VERSION ""

NS_ :

BS_:

BU_: Buf1 Buf2 Buf3

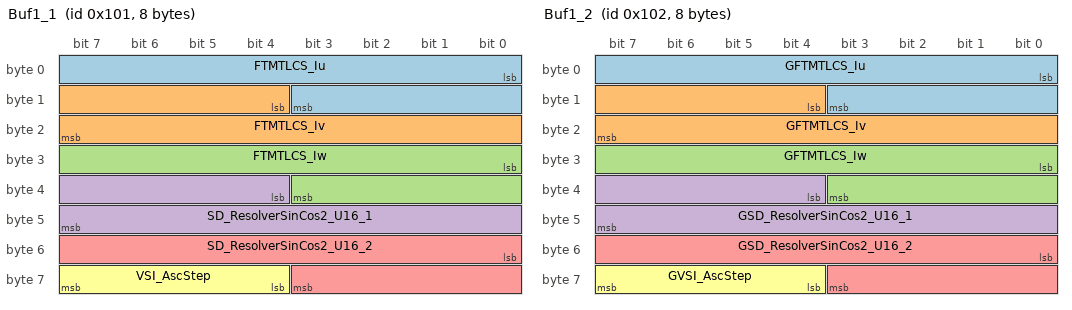
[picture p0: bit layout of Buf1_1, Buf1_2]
BO_ 257 Buf1_1: 8 Buf1
 SG_ FTMTLCS_Iu : 0|12@1+ (1,-2000) [-2000|2095] "" Vector__XXX
 SG_ FTMTLCS_Iv : 12|12@1+ (1,-2000) [-2000|2095] "" Vector__XXX
 SG_ FTMTLCS_Iw : 24|12@1+ (1,-2000) [-2000|2095] "" Vector__XXX
 SG_ SD_ResolverSinCos2_U16_1 : 36|12@1+ (1,0) [0|4095] "" Vector__XXX
 SG_ SD_ResolverSinCos2_U16_2 : 48|12@1+ (1,0) [0|4095] "" Vector__XXX
 SG_ VSI_AscStep : 60|4@1+ (1,0) [0|15] "" Vector__XXX

BO_ 258 Buf1_2: 8 Buf1
 SG_ GFTMTLCS_Iu : 0|12@1+ (1,-2000) [-2000|2095] "" Vector__XXX
 SG_ GFTMTLCS_Iv : 12|12@1+ (1,-2000) [-2000|2095] "" Vector__XXX
 SG_ GFTMTLCS_Iw : 24|12@1+ (1,-2000) [-2000|2095] "" Vector__XXX
 SG_ GSD_ResolverSinCos2_U16_1 : 36|12@1+ (1,0) [0|4095] "" Vector__XXX
 SG_ GSD_ResolverSinCos2_U16_2 : 48|12@1+ (1,0) [0|4095] "" Vector__XXX
 SG_ GVSI_AscStep : 60|4@1+ (1,0) [0|15] "" Vector__XXX

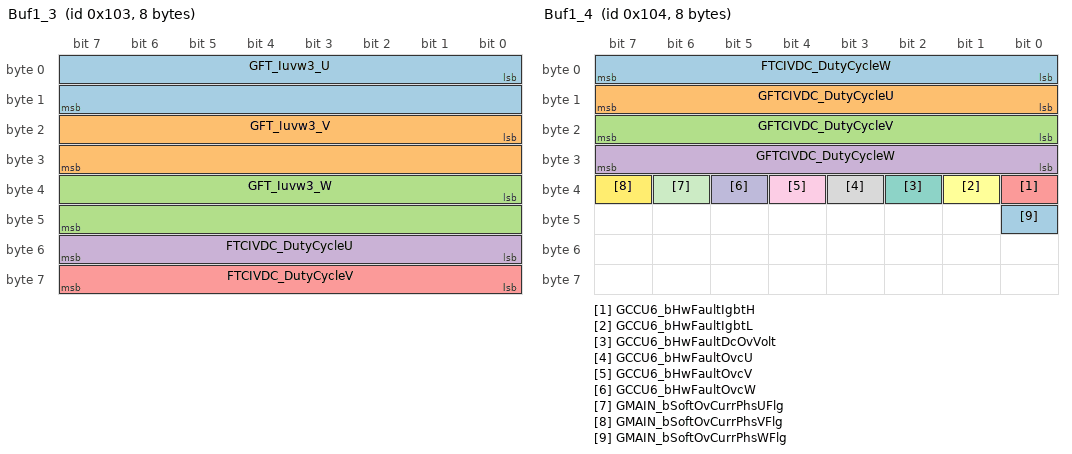
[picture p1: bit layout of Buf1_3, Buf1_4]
BO_ 259 Buf1_3: 8 Buf1
 SG_ GFT_Iuvw3_U : 0|16@1+ (1,0) [0|65535] "" Vector__XXX
 SG_ GFT_Iuvw3_V : 16|16@1+ (1,0) [0|65535] "" Vector__XXX
 SG_ GFT_Iuvw3_W : 32|16@1+ (1,0) [0|65535] "" Vector__XXX
 SG_ FTCIVDC_DutyCycleU : 48|8@1+ (0.01,-1) [-1|1.55] "" Vector__XXX
 SG_ FTCIVDC_DutyCycleV : 56|8@1+ (0.01,-1) [-1|1.55] "" Vector__XXX

BO_ 260 Buf1_4: 8 Buf1
 SG_ FTCIVDC_DutyCycleW : 0|8@1+ (0.01,-1) [-1|1.55] "" Vector__XXX
 SG_ GFTCIVDC_DutyCycleU : 8|8@1+ (0.01,-1) [-1|1.55] "" Vector__XXX
 SG_ GFTCIVDC_DutyCycleV : 16|8@1+ (0.01,-1) [-1|1.55] "" Vector__XXX
 SG_ GFTCIVDC_DutyCycleW : 24|8@1+ (0.01,-1) [-1|1.55] "" Vector__XXX
 SG_ GCCU6_bHwFaultIgbtH : 32|1@1+ (1,0) [0|1] "" Vector__XXX
 SG_ GCCU6_bHwFaultIgbtL : 33|1@1+ (1,0) [0|1] "" Vector__XXX
 SG_ GCCU6_bHwFaultDcOvVolt : 34|1@1+ (1,0) [0|1] "" Vector__XXX
 SG_ GCCU6_bHwFaultOvcU : 35|1@1+ (1,0) [0|1] "" Vector__XXX
 SG_ GCCU6_bHwFaultOvcV : 36|1@1+ (1,0) [0|1] "" Vector__XXX
 SG_ GCCU6_bHwFaultOvcW : 37|1@1+ (1,0) [0|1] "" Vector__XXX
 SG_ GMAIN_bSoftOvCurrPhsUFlg : 38|1@1+ (1,0) [0|1] "" Vector__XXX
 SG_ GMAIN_bSoftOvCurrPhsVFlg : 39|1@1+ (1,0) [0|1] "" Vector__XXX
 SG_ GMAIN_bSoftOvCurrPhsWFlg : 40|1@1+ (1,0) [0|1] "" Vector__XXX

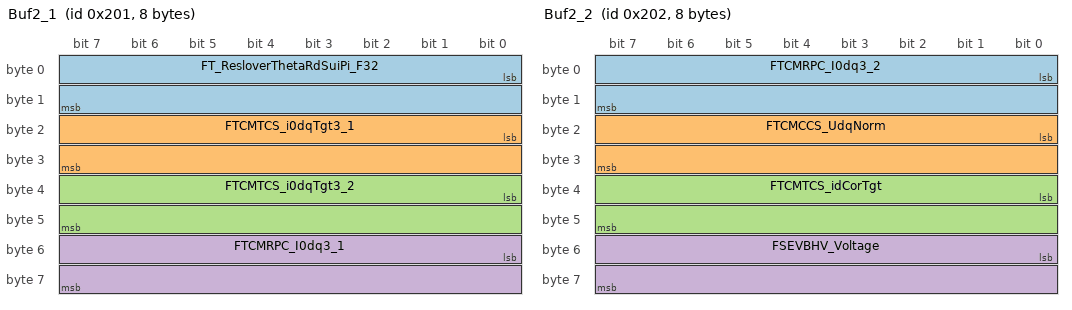
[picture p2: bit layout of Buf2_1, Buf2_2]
BO_ 513 Buf2_1: 8 Buf2
 SG_ FT_ResloverThetaRdSuiPi_F32 : 0|16@1+ (0.001,-4) [-4|61.535] "" Vector__XXX
 SG_ FTCMTCS_i0dqTgt3_1 : 16|16@1+ (1,-5000) [-5000|60535] "" Vector__XXX
 SG_ FTCMTCS_i0dqTgt3_2 : 32|16@1+ (1,-5000) [-5000|60535] "" Vector__XXX
 SG_ FTCMRPC_I0dq3_1 : 48|16@1+ (1,-5000) [-5000|60535] "" Vector__XXX

BO_ 514 Buf2_2: 8 Buf2
 SG_ FTCMRPC_I0dq3_2 : 0|16@1+ (1,-5000) [-5000|60535] "" Vector__XXX
 SG_ FTCMCCS_UdqNorm : 16|16@1+ (1,0) [0|65535] "" Vector__XXX
 SG_ FTCMTCS_idCorTgt : 32|16@1+ (1,-5000) [-5000|60535] "" Vector__XXX
 SG_ FSEVBHV_Voltage : 48|16@1+ (1,0) [0|65535] "" Vector__XXX

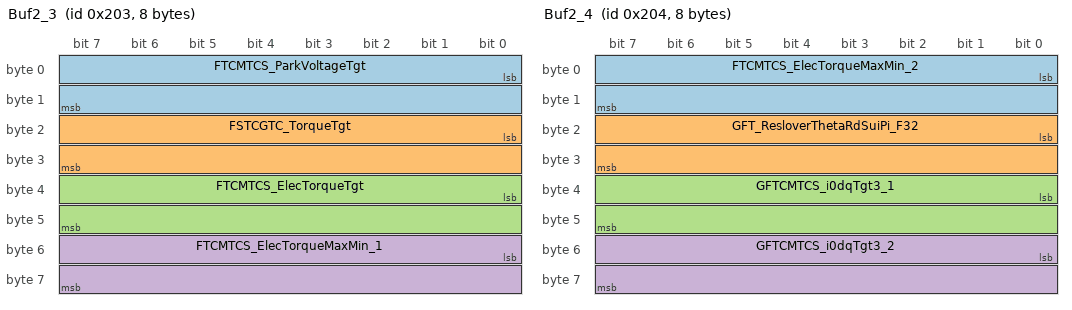
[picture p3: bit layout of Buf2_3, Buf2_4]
BO_ 515 Buf2_3: 8 Buf2
 SG_ FTCMTCS_ParkVoltageTgt : 0|16@1+ (0.1,0) [0|6553.5] "" Vector__XXX
 SG_ FSTCGTC_TorqueTgt : 16|16@1+ (0.1,-1500) [-1500|5053.5] "" Vector__XXX
 SG_ FTCMTCS_ElecTorqueTgt : 32|16@1+ (0.1,-1500) [-1500|5053.5] "" Vector__XXX
 SG_ FTCMTCS_ElecTorqueMaxMin_1 : 48|16@1+ (0.1,0) [0|65535] "" Vector__XXX

BO_ 516 Buf2_4: 8 Buf2
 SG_ FTCMTCS_ElecTorqueMaxMin_2 : 0|16@1+ (0.1,-1500) [-1500|5053.5] "" Vector__XXX
 SG_ GFT_ResloverThetaRdSuiPi_F32 : 16|16@1+ (0.001,-4) [-4|61.535] "" Vector__XXX
 SG_ GFTCMTCS_i0dqTgt3_1 : 32|16@1+ (1,-5000) [-5000|60535] "" Vector__XXX
 SG_ GFTCMTCS_i0dqTgt3_2 : 48|16@1+ (1,-5000) [-5000|60535] "" Vector__XXX

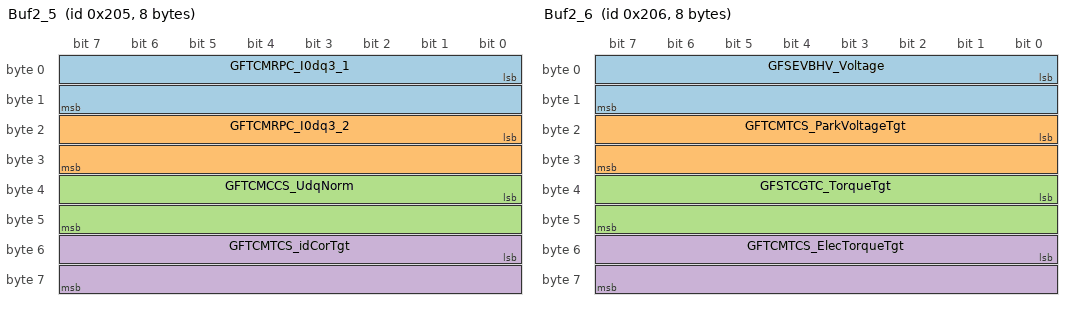
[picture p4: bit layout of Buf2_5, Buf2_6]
BO_ 517 Buf2_5: 8 Buf2
 SG_ GFTCMRPC_I0dq3_1 : 0|16@1+ (1,-5000) [-5000|60535] "" Vector__XXX
 SG_ GFTCMRPC_I0dq3_2 : 16|16@1+ (1,-5000) [-5000|60535] "" Vector__XXX
 SG_ GFTCMCCS_UdqNorm : 32|16@1+ (1,0) [0|65535] "" Vector__XXX
 SG_ GFTCMTCS_idCorTgt : 48|16@1+ (1,-5000) [-50000|60535] "" Vector__XXX

BO_ 518 Buf2_6: 8 Buf2
 SG_ GFSEVBHV_Voltage : 0|16@1+ (1,0) [0|65535] "" Vector__XXX
 SG_ GFTCMTCS_ParkVoltageTgt : 16|16@1+ (0.1,0) [0|6553.5] "" Vector__XXX
 SG_ GFSTCGTC_TorqueTgt : 32|16@1+ (0.1,-1500) [-1500|5053.5] "" Vector__XXX
 SG_ GFTCMTCS_ElecTorqueTgt : 48|16@1+ (0.1,-1500) [-1500|5053.5] "" Vector__XXX

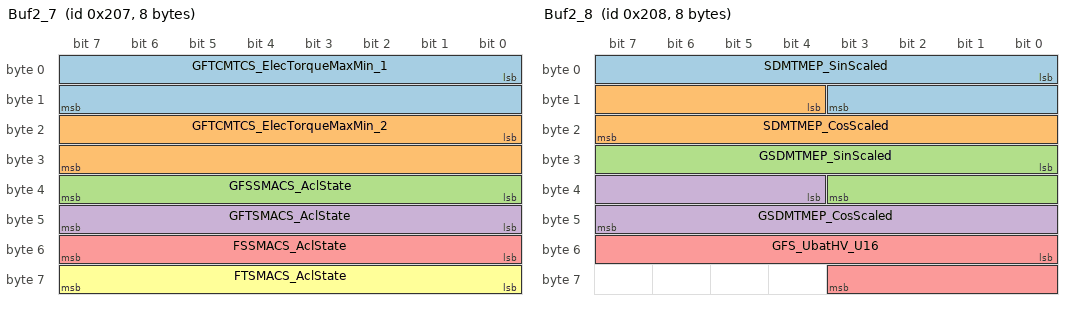
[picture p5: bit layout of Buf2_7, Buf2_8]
BO_ 519 Buf2_7: 8 Buf2
 SG_ GFTCMTCS_ElecTorqueMaxMin_1 : 0|16@1+ (0.1,0) [0|6553.5] "" Vector__XXX
 SG_ GFTCMTCS_ElecTorqueMaxMin_2 : 16|16@1+ (0.1,-1500) [-1500|5053.5] "" Vector__XXX
 SG_ GFSSMACS_AclState : 32|8@1+ (1,0) [0|255] "" Vector__XXX
 SG_ GFTSMACS_AclState : 40|8@1+ (1,0) [0|255] "" Vector__XXX
 SG_ FSSMACS_AclState : 48|8@1+ (1,0) [0|255] "" Vector__XXX
 SG_ FTSMACS_AclState : 56|8@1+ (1,0) [0|255] "" Vector__XXX

BO_ 520 Buf2_8: 8 Buf2
 SG_ SDMTMEP_SinScaled : 0|12@1+ (1,0) [0|4095] "" Vector__XXX
 SG_ SDMTMEP_CosScaled : 12|12@1+ (1,0) [0|4095] "" Vector__XXX
 SG_ GSDMTMEP_SinScaled : 24|12@1+ (1,0) [0|4095] "" Vector__XXX
 SG_ GSDMTMEP_CosScaled : 36|12@1+ (1,0) [0|4095] "" Vector__XXX
 SG_ GFS_UbatHV_U16 : 48|12@1+ (1,0) [0|4095] "" Vector__XXX

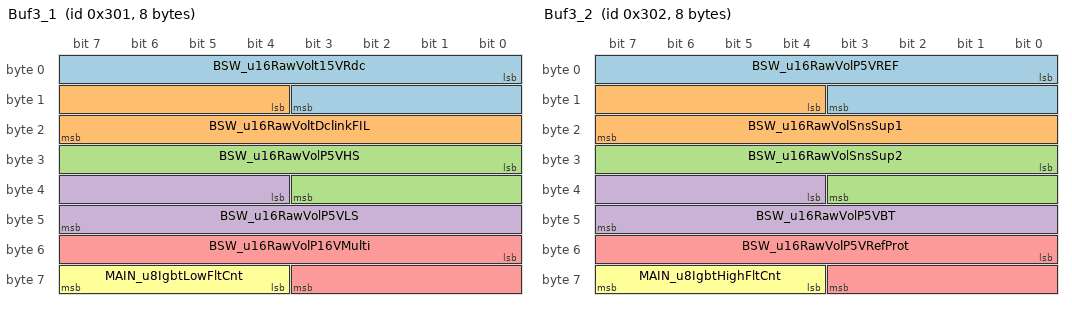
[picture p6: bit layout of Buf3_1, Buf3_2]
BO_ 769 Buf3_1: 8 Buf3
 SG_ BSW_u16RawVolt15VRdc : 0|12@1+ (1,0) [0|4095] "" Vector__XXX
 SG_ BSW_u16RawVoltDclinkFIL : 12|12@1+ (1,0) [0|4095] "" Vector__XXX
 SG_ BSW_u16RawVolP5VHS : 24|12@1+ (1,0) [0|4095] "" Vector__XXX
 SG_ BSW_u16RawVolP5VLS : 36|12@1+ (1,0) [0|4095] "" Vector__XXX
 SG_ BSW_u16RawVolP16VMulti : 48|12@1+ (1,0) [0|4095] "" Vector__XXX
 SG_ MAIN_u8IgbtLowFltCnt : 60|4@1+ (1,0) [0|15] "" Vector__XXX

BO_ 770 Buf3_2: 8 Buf3
 SG_ BSW_u16RawVolP5VREF : 0|12@1+ (1,0) [0|4095] "" Vector__XXX
 SG_ BSW_u16RawVolSnsSup1 : 12|12@1+ (1,0) [0|4095] "" Vector__XXX
 SG_ BSW_u16RawVolSnsSup2 : 24|12@1+ (1,0) [0|4095] "" Vector__XXX
 SG_ BSW_u16RawVolP5VBT : 36|12@1+ (1,0) [0|4095] "" Vector__XXX
 SG_ BSW_u16RawVolP5VRefProt : 48|12@1+ (1,0) [0|4095] "" Vector__XXX
 SG_ MAIN_u8IgbtHighFltCnt : 60|4@1+ (1,0) [0|15] "" Vector__XXX

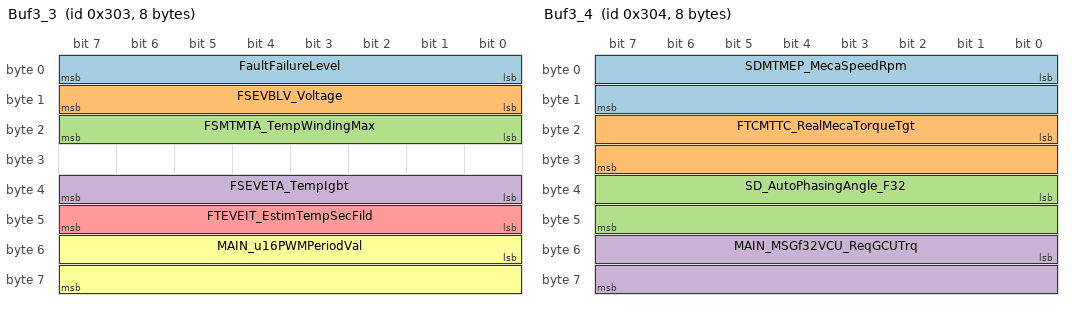
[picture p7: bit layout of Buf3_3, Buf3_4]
BO_ 771 Buf3_3: 8 Buf3
 SG_ FaultFailureLevel : 0|8@1+ (1,0) [0|255] "" Vector__XXX
 SG_ FSEVBLV_Voltage : 8|8@1+ (0.2,0) [0|51] "" Vector__XXX
 SG_ FSMTMTA_TempWindingMax : 16|8@1+ (1,-50) [-50|205] "" Vector__XXX
 SG_ FSEVETA_TempIgbt : 32|8@1+ (1,-50) [-50|205] "" Vector__XXX
 SG_ FTEVEIT_EstimTempSecFild : 40|8@1+ (1,-50) [-50|205] "" Vector__XXX
 SG_ MAIN_u16PWMPeriodVal : 48|16@1+ (1,0) [0|65535] "" Vector__XXX

BO_ 772 Buf3_4: 8 Buf3
 SG_ SDMTMEP_MecaSpeedRpm : 0|16@1+ (1,-20000) [-20000|45535] "" Vector__XXX
 SG_ FTCMTTC_RealMecaTorqueTgt : 16|16@1+ (0.1,-3000) [-3000|3553.5] "" Vector__XXX
 SG_ SD_AutoPhasingAngle_F32 : 32|16@1+ (0.0001,-3) [-3|3.5535] "" Vector__XXX
 SG_ MAIN_MSGf32VCU_ReqGCUTrq : 48|16@1+ (1,-1024) [-1024|64511] "" Vector__XXX

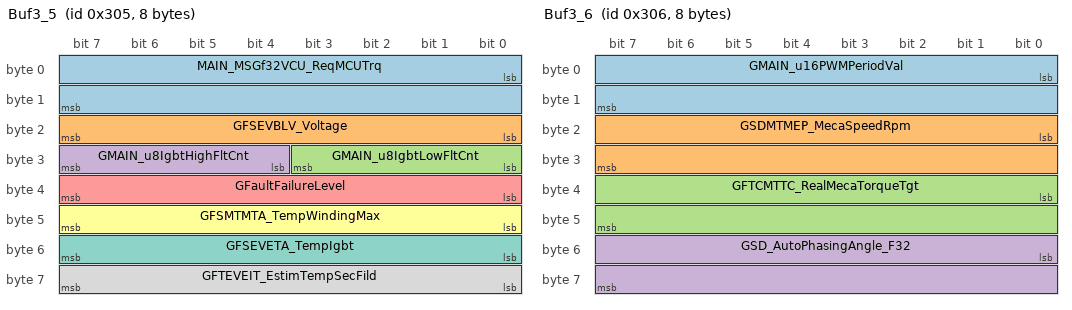
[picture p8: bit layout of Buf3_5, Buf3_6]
BO_ 773 Buf3_5: 8 Buf3
 SG_ MAIN_MSGf32VCU_ReqMCUTrq : 0|16@1+ (1,-1024) [-1024|64511] "" Vector__XXX
 SG_ GFSEVBLV_Voltage : 16|8@1+ (0.2,0) [0|51] "" Vector__XXX
 SG_ GMAIN_u8IgbtLowFltCnt : 24|4@1+ (1,0) [0|15] "" Vector__XXX
 SG_ GMAIN_u8IgbtHighFltCnt : 28|4@1+ (1,0) [0|15] "" Vector__XXX
 SG_ GFaultFailureLevel : 32|8@1+ (1,0) [0|255] "" Vector__XXX
 SG_ GFSMTMTA_TempWindingMax : 40|8@1+ (1,-50) [-50|205] "" Vector__XXX
 SG_ GFSEVETA_TempIgbt : 48|8@1+ (1,-50) [-50|205] "" Vector__XXX
 SG_ GFTEVEIT_EstimTempSecFild : 56|8@1+ (1,-50) [-50|205] "" Vector__XXX

BO_ 774 Buf3_6: 8 Buf3
 SG_ GMAIN_u16PWMPeriodVal : 0|16@1+ (1,0) [0|65535] "" Vector__XXX
 SG_ GSDMTMEP_MecaSpeedRpm : 16|16@1+ (1,-20000) [-20000|45535] "" Vector__XXX
 SG_ GFTCMTTC_RealMecaTorqueTgt : 32|16@1+ (0.1,-3000) [-3000|3553.5] "" Vector__XXX
 SG_ GSD_AutoPhasingAngle_F32 : 48|16@1+ (0.0001,-3) [-3|3.5535] "" Vector__XXX

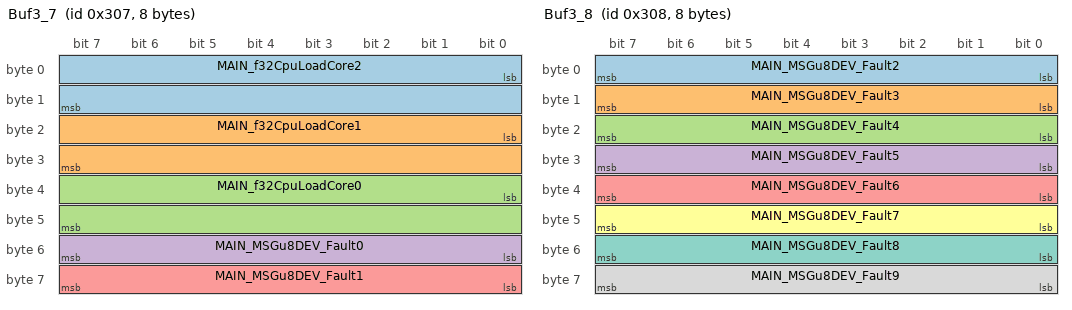
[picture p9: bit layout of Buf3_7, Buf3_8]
BO_ 775 Buf3_7: 8 Buf3
 SG_ MAIN_f32CpuLoadCore2 : 0|16@1+ (1,0) [0|65535] "" Vector__XXX
 SG_ MAIN_f32CpuLoadCore1 : 16|16@1+ (1,0) [0|65535] "" Vector__XXX
 SG_ MAIN_f32CpuLoadCore0 : 32|16@1+ (1,0) [0|65535] "" Vector__XXX
 SG_ MAIN_MSGu8DEV_Fault0 : 48|8@1+ (1,0) [0|255] "" Vector__XXX
 SG_ MAIN_MSGu8DEV_Fault1 : 56|8@1+ (1,0) [0|255] "" Vector__XXX

BO_ 776 Buf3_8: 8 Buf3
 SG_ MAIN_MSGu8DEV_Fault2 : 0|8@1+ (1,0) [0|255] "" Vector__XXX
 SG_ MAIN_MSGu8DEV_Fault3 : 8|8@1+ (1,0) [0|255] "" Vector__XXX
 SG_ MAIN_MSGu8DEV_Fault4 : 16|8@1+ (1,0) [0|255] "" Vector__XXX
 SG_ MAIN_MSGu8DEV_Fault5 : 24|8@1+ (1,0) [0|255] "" Vector__XXX
 SG_ MAIN_MSGu8DEV_Fault6 : 32|8@1+ (1,0) [0|255] "" Vector__XXX
 SG_ MAIN_MSGu8DEV_Fault7 : 40|8@1+ (1,0) [0|255] "" Vector__XXX
 SG_ MAIN_MSGu8DEV_Fault8 : 48|8@1+ (1,0) [0|255] "" Vector__XXX
 SG_ MAIN_MSGu8DEV_Fault9 : 56|8@1+ (1,0) [0|255] "" Vector__XXX

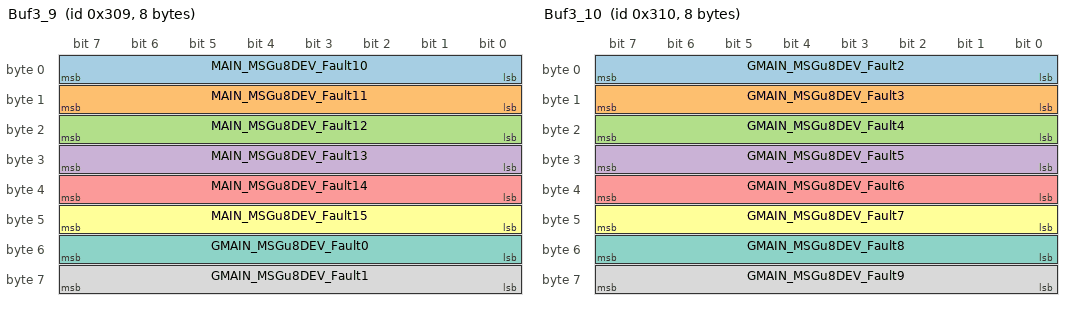
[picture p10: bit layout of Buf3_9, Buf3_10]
BO_ 777 Buf3_9: 8 Buf3
 SG_ MAIN_MSGu8DEV_Fault10 : 0|8@1+ (1,0) [0|255] "" Vector__XXX
 SG_ MAIN_MSGu8DEV_Fault11 : 8|8@1+ (1,0) [0|255] "" Vector__XXX
 SG_ MAIN_MSGu8DEV_Fault12 : 16|8@1+ (1,0) [0|255] "" Vector__XXX
 SG_ MAIN_MSGu8DEV_Fault13 : 24|8@1+ (1,0) [0|255] "" Vector__XXX
 SG_ MAIN_MSGu8DEV_Fault14 : 32|8@1+ (1,0) [0|255] "" Vector__XXX
 SG_ MAIN_MSGu8DEV_Fault15 : 40|8@1+ (1,0) [0|255] "" Vector__XXX
 SG_ GMAIN_MSGu8DEV_Fault0 : 48|8@1+ (1,0) [0|255] "" Vector__XXX
 SG_ GMAIN_MSGu8DEV_Fault1 : 56|8@1+ (1,0) [0|255] "" Vector__XXX

BO_ 784 Buf3_10: 8 Buf3
 SG_ GMAIN_MSGu8DEV_Fault2 : 0|8@1+ (1,0) [0|255] "W" Vector__XXX
 SG_ GMAIN_MSGu8DEV_Fault3 : 8|8@1+ (1,0) [0|255] "" Vector__XXX
 SG_ GMAIN_MSGu8DEV_Fault4 : 16|8@1+ (1,0) [0|255] "" Vector__XXX
 SG_ GMAIN_MSGu8DEV_Fault5 : 24|8@1+ (1,0) [0|255] "" Vector__XXX
 SG_ GMAIN_MSGu8DEV_Fault6 : 32|8@1+ (1,0) [0|255] "" Vector__XXX
 SG_ GMAIN_MSGu8DEV_Fault7 : 40|8@1+ (1,0) [0|255] "" Vector__XXX
 SG_ GMAIN_MSGu8DEV_Fault8 : 48|8@1+ (1,0) [0|255] "" Vector__XXX
 SG_ GMAIN_MSGu8DEV_Fault9 : 56|8@1+ (1,0) [0|255] "" Vector__XXX

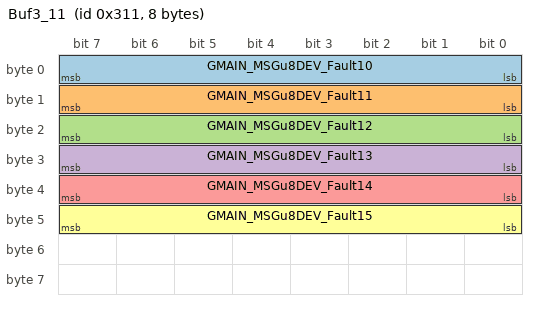
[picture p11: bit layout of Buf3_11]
BO_ 785 Buf3_11: 8 Buf3
 SG_ GMAIN_MSGu8DEV_Fault10 : 0|8@1+ (1,0) [0|255] "W" Vector__XXX
 SG_ GMAIN_MSGu8DEV_Fault11 : 8|8@1+ (1,0) [0|255] "" Vector__XXX
 SG_ GMAIN_MSGu8DEV_Fault12 : 16|8@1+ (1,0) [0|255] "" Vector__XXX
 SG_ GMAIN_MSGu8DEV_Fault13 : 24|8@1+ (1,0) [0|255] "" Vector__XXX
 SG_ GMAIN_MSGu8DEV_Fault14 : 32|8@1+ (1,0) [0|255] "" Vector__XXX
 SG_ GMAIN_MSGu8DEV_Fault15 : 40|8@1+ (1,0) [0|255] "" Vector__XXX

BA_DEF_ SG_  "GenSigSendType" ENUM  "Cyclic","OnWrite","OnWriteWithRepetition","OnChange","OnChangeWithRepetition","IfActive","IfActiveWithRepetition","NoSigSendType";
BA_DEF_ BO_  "GenMsgCycleTime" INT 0 0;
BA_DEF_ BO_  "GenMsgSendType" ENUM  "Cyclic","not_used","not_used","not_used","not_used","Cyclic","not_used","IfActive","NoMsgSendType";
BA_DEF_  "DBName" STRING ;
BA_DEF_  "BusType" STRING ;
BA_DEF_DEF_  "GenSigSendType" "Cyclic";
BA_DEF_DEF_  "GenMsgCycleTime" 0;
BA_DEF_DEF_  "GenMsgSendType" "NoMsgSendType";
BA_DEF_DEF_  "DBName" "";
BA_DEF_DEF_  "BusType" "CAN";
BA_ "DBName" "FaultRecord_Test.dbc";
BA_ "GenMsgCycleTime" BO_ 257 100;
BA_ "GenMsgCycleTime" BO_ 258 100;
BA_ "GenMsgCycleTime" BO_ 259 100;
BA_ "GenMsgCycleTime" BO_ 260 100;
BA_ "GenMsgCycleTime" BO_ 513 1000;
BA_ "GenMsgCycleTime" BO_ 514 1000;
BA_ "GenMsgCycleTime" BO_ 515 1000;
BA_ "GenMsgCycleTime" BO_ 516 1000;
BA_ "GenMsgCycleTime" BO_ 517 1000;
BA_ "GenMsgCycleTime" BO_ 518 1000;
BA_ "GenMsgCycleTime" BO_ 519 1000;
BA_ "GenMsgCycleTime" BO_ 520 1000;
BA_ "GenMsgCycleTime" BO_ 769 10000;
BA_ "GenMsgCycleTime" BO_ 770 10000;
BA_ "GenMsgCycleTime" BO_ 771 10000;
BA_ "GenMsgCycleTime" BO_ 772 10000;
BA_ "GenMsgCycleTime" BO_ 773 10000;
BA_ "GenMsgCycleTime" BO_ 774 10000;
BA_ "GenMsgCycleTime" BO_ 775 10000;
BA_ "GenMsgCycleTime" BO_ 776 10000;
BA_ "GenMsgCycleTime" BO_ 777 10000;
BA_ "GenMsgCycleTime" BO_ 784 10000;
BA_ "GenMsgCycleTime" BO_ 785 10000;
